# PIC32CZ4010CA90176 device description
Architecture: CORTEX-M7; Family: PIC32C; Series: PIC32CZCA90
Registers are 32-bit, read-write, reset 0x0 unless marked. A register's access mark holds for its fields unless they carry their own. Offsets are from the block's base; [hi:lo] are bit positions; lines under a group give offsets from that group; {n}, {i} and the like mark numbered series.

## ETM — Embedded Trace Macrocell
Instances: ETM 0xE0041000
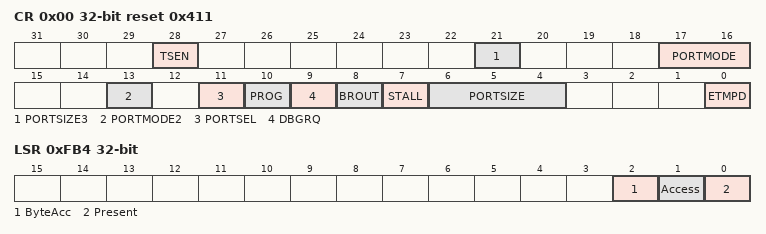
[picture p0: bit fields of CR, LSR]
0x00 CR reset 0x411 — ETM Main Control Register
  [28] TSEN — TimeStamp Enable
  [21] PORTSIZE3 — Port Size bit 3
  [17:16] PORTMODE — Port Mode bits 1:0
  [13] PORTMODE2 — Port Mode bit 2
  [11] PORTSEL — ETM Port Select
  [10] PROG — ETM Programming
  [9] DBGRQ — Debug Request Control
  [8] BROUT — Branch Output
  [7] STALL — Stall Processor
  [6:4] PORTSIZE — Port Size bits 2:0
  [0] ETMPD — ETM Power Down
0x04 CCR ro reset 0x8C802000 — ETM Configuration Code Register
0x08 TRIGGER reset not defined — ETM Trigger Event Register
0x10 SR reset not defined — ETM Status Register
0x14 SCR ro reset 0x20D09 (atomic clear of SR) — ETM System Configuration Register
0x20 TEEVR reset not defined — ETM TraceEnable Event Register
0x24 TECR1 reset not defined — ETM TraceEnable Control 1 Register
0x28 FFLR reset not defined — ETM FIFO Full Level Register
0x140 CNTRLDVR1 reset not defined — ETM Free-running Counter Reload Value
0x1E0 SYNCFR ro reset 0x400 — ETM Synchronization Frequency Register
0x1E4 IDR ro reset 0x4114F250 — ETM ID Register
0x1E8 CCER ro reset 0x18541800 — ETM Configuration Code Extension Register
0x1F0 TESSEICR reset not defined — ETM TraceEnable Start/Stop EmbeddedICE Control Register
0x1F8 TSEVT reset not defined — ETM TimeStamp Event Register
0x200 TRACEIDR — ETM CoreSight Trace ID Register
0x208 IDR2 ro — ETM ID Register 2
0x314 PDSR ro reset 0x1 — ETM Device Power-Down Status Register
0xEE0 ITMISCIN ro reset not defined — ETM Integration Test Miscellaneous Inputs
0xEE8 ITTRIGOUT wo reset not defined — ETM Integration Test Trigger Out
0xEF0 ITATBCTR2 ro reset not defined — ETM Integration Test ATB Control 2
0xEF8 ITATBCTR0 wo reset not defined — ETM Integration Test ATB Control 0
0xF00 ITCTRL — ETM Integration Mode Control Register
  [0] INTEGRATION
0xFA0 CLAIMSET reset not defined (atomic set) — ETM Claim Tag Set Register
0xFA4 CLAIMCLR reset not defined (atomic clear) — ETM Claim Tag Clear Register
0xFB0 LAR wo reset not defined — ETM Lock Access Register
0xFB4 LSR ro reset not defined — ETM Lock Status Register
  [2] ByteAcc, [1] Access, [0] Present
0xFB8 AUTHSTATUS ro reset not defined — ETM Authentication Status Register
0xFCC DEVTYPE ro reset 0x13 — ETM CoreSight Device Type Register
0xFD0 PIDR4 ro reset 0x4 — ETM Peripheral Identification Register #4
{0xFC0+4i} PIDR{i} ro (i=5..7) — ETM Peripheral Identification Register #{i}
0xFE0 PIDR0 ro reset 0x25 — ETM Peripheral Identification Register #0
0xFE4 PIDR1 ro reset 0xB9 — ETM Peripheral Identification Register #1
0xFE8 PIDR2 ro reset 0xB — ETM Peripheral Identification Register #2
0xFEC PIDR3 ro — ETM Peripheral Identification Register #3
0xFF0 CIDR0 ro reset 0xD — ETM Component Identification Register #0
0xFF4 CIDR1 ro reset 0x90 — ETM Component Identification Register #1
0xFF8 CIDR2 ro reset 0x5 — ETM Component Identification Register #2
0xFFC CIDR3 ro reset 0xB1 — ETM Component Identification Register #3

## EVSYS — Event System Interface
Instances: EVSYS 0x44860000
0x00 CTRLA 8-bit wo — Control
  [0] SWRST — Software Reset
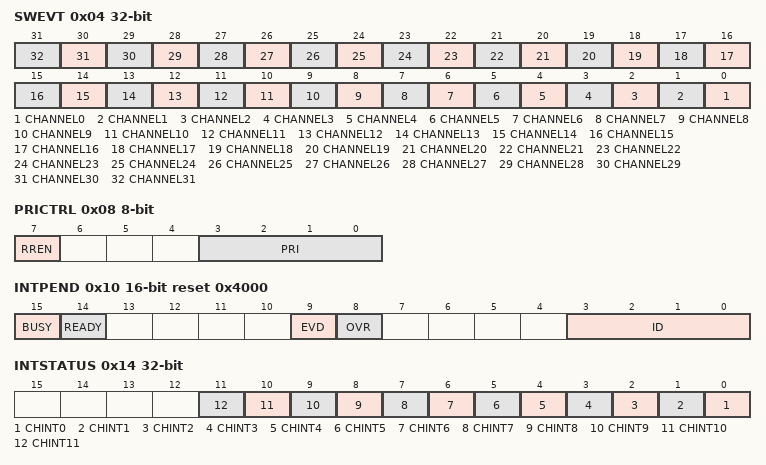
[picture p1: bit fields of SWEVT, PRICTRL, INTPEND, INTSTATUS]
0x04 SWEVT wo — Software Event
  [n] CHANNEL{n} (n=0..31) — Channel {n} Software Selection
0x08 PRICTRL 8-bit — Priority Control
  [7] RREN — Round-Robin Scheduling Enable
  [3:0] PRI — Channel Priority Number
0x10 INTPEND 16-bit reset 0x4000 — Channel Pending Interrupt
  [15] BUSY
  [14] READY
  [9] EVD — Channel Event Detected
  [8] OVR — Channel Overrun
  [3:0] ID — Channel ID
0x14 INTSTATUS ro — Interrupt Status
  [n] CHINT{n} (n=0..11) — Channel {n} Pending Interrupt
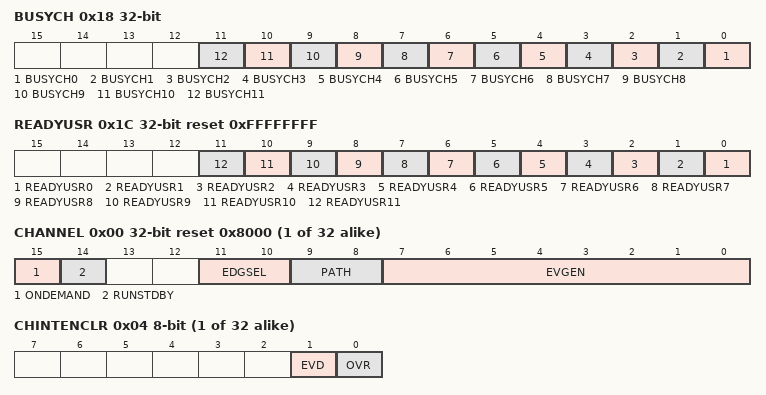
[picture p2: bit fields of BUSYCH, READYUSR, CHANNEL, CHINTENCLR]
0x18 BUSYCH ro — Busy Channels
  [n] BUSYCH{n} (n=0..11) — Busy Channel {n}
0x1C READYUSR ro reset 0xFFFFFFFF — Ready Users
  [n] READYUSR{n} (n=0..11) — Ready User for Channel {n}
{0x20+8i} CHANNEL[{i}] (i=0..31) group
  0x00 CHANNEL reset 0x8000 — Channel n Control
    [15] ONDEMAND — Generic Clock On Demand
    [14] RUNSTDBY — Run in standby
    [11:10] EDGSEL — Edge Detection Selection
      0=NO_EVT_OUTPUT (No event output when using the resynchronized or synchronous path); 1=RISING_EDGE (Event detection only on the rising edge of the signal from the event generator when using the resynchronized or synchronous path); 2=FALLING_EDGE (Event detection only on the falling edge of the signal from the event generator when using the resynchronized or synchronous path); 3=BOTH_EDGES (Event detection on rising and falling edges of the signal from the event generator when using the resynchronized or synchronous path)
    [9:8] PATH — Path Selection
      0=ASYNCHRONOUS (Asynchronous path); 1=RESYNCHRONIZED (Resynchronized path)
    [7:0] EVGEN — Event Generator Selection
  0x04 CHINTENCLR 8-bit (atomic clear) — Channel n Interrupt Enable Clear
    [1] EVD — Channel Event Detected Interrupt Disable
    [0] OVR — Channel Overrun Interrupt Disable
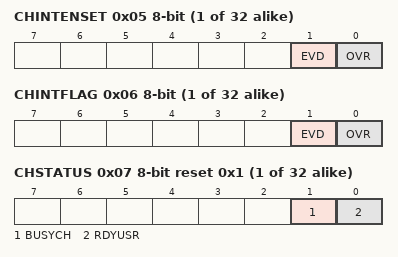
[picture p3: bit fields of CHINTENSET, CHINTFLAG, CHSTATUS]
  0x05 CHINTENSET 8-bit (atomic set) — Channel n Interrupt Enable Set
    [1] EVD — Channel Event Detected Interrupt Enable
    [0] OVR — Channel Overrun Interrupt Enable
  0x06 CHINTFLAG 8-bit (atomic clear) — Channel n Interrupt Flag Status and Clear
    [1] EVD — Channel Event Detected
    [0] OVR — Channel Overrun
  0x07 CHSTATUS 8-bit ro reset 0x1 — Channel n Status
    [1] BUSYCH — Busy Channel
    [0] RDYUSR — Ready User
{0x120+i} USER[{i}] (i=0..116) 8-bit — User Multiplexer n
  [5:0] CHANNEL — Channel Event Selection

## Notices in the file
Copyright (c) 2021 Microchip Technology Inc.
SPDX-License-Identifier: Apache-2.0
Licensed under the Apache License, Version 2.0 (the "License");
you may not use this file except in compliance with the License.
You may obtain a copy of the License at
http://www.apache.org/licenses/LICENSE-2.0
Unless required by applicable law or agreed to in writing, software
distributed under the License is distributed on an "AS IS" BASIS,
WITHOUT WARRANTIES OR CONDITIONS OF ANY KIND, either express or implied.
See the License for the specific language governing permissions and
limitations under the License.
